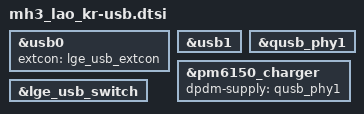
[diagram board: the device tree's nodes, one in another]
/* Copyright (c) 2018, The Linux Foundation. All rights reserved.
 *
 * This program is free software; you can redistribute it and/or modify
 * it under the terms of the GNU General Public License version 2 and
 * only version 2 as published by the Free Software Foundation.
 *
 * This program is distributed in the hope that it will be useful,
 * but WITHOUT ANY WARRANTY; without even the implied warranty of
 * MERCHANTABILITY or FITNESS FOR A PARTICULAR PURPOSE.  See the
 * GNU General Public License for more details.
 */

&usb0 {
	status = "okay";
	extcon = <&lge_usb_extcon>;
	/delete-property/ dpdm-supply;
};

&usb1 {
	status = "okay";
};

&qusb_phy1 {
	status = "okay";
};

&pm6150_charger {
	dpdm-supply = <&qusb_phy1>;
};

&lge_usb_switch {
	status = "okay";
};
